AUTOSAR XML (schema 00044)
package /E40_Platform_System_SystemPackage/Components
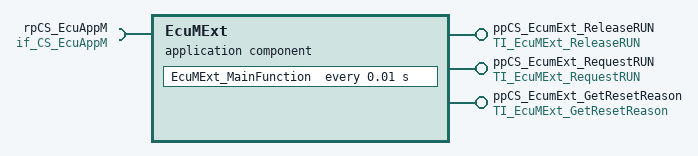
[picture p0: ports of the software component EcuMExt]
  application sw component type EcuMExt
    provide port ppCS_EcumExt_ReleaseRUN: server-com-spec{operation=ReleaseRUN, queue-length=1}, provided-interface=TI_EcuMExt_ReleaseRUN
    provide port ppCS_EcumExt_RequestRUN: server-com-spec{operation=RequestRUN, queue-length=1}, provided-interface=TI_EcuMExt_RequestRUN
    require port rpCS_EcuAppM: required-com-specs=[EcuAppM_SetWakeupSources, Init], required-interface=if_CS_EcuAppM
    provide port ppCS_EcumExt_GetResetReason: server-com-spec{operation=GetResetReason, queue-length=1}, provided-interface=TI_EcuMExt_GetResetReason
    behavior IB_EcuMExt
      timing event TEEcuMExt_MainFunction: start-on-event=EcuMExt_MainFunction, period=0.01
      operation invoked event OIE_ppCS_EcumExt_ReleaseRUN_EcuMExt_ReleaseRUNTrigByReleaseRUN: start-on-event=EcuMExt_ReleaseRUN, operation=ppCS_EcumExt_ReleaseRUN.ReleaseRUN
      operation invoked event OIE_ppCS_EcumExt_RequestRUN_EcuMExt_RequestRUNTrigByRequestRUN: start-on-event=EcuMExt_RequestRUN, operation=ppCS_EcumExt_RequestRUN.RequestRUN
      operation invoked event OIE_ppCS_EcumExt_GetResetReason_EcuMExt_GetResetReasonTrigByGetResetReason: start-on-event=EcuMExt_GetResetReason, operation=ppCS_EcumExt_GetResetReason.GetResetReason
      port-api-options:
        enable-take-address=false, indirect-api=false, port=ppCS_EcumExt_ReleaseRUN
        enable-take-address=false, indirect-api=false, port=ppCS_EcumExt_RequestRUN
        enable-take-address=false, indirect-api=false, port=rpCS_EcuAppM
        enable-take-address=false, indirect-api=false, port=ppCS_EcumExt_GetResetReason
      4 x runnable, all with can-be-invoked-concurrently=true:
        EcuMExt_MainFunction
          sync call OA_rpCS_EcuAppM_Init: operation=rpCS_EcuAppM.Init
          sync call OA_rpCS_EcuAppM_EcuAppM_SetWakeupSources: operation=rpCS_EcuAppM.EcuAppM_SetWakeupSources
        EcuMExt_ReleaseRUN
          sync call OA_rpCS_EcuAppM_Init: operation=rpCS_EcuAppM.Init
          sync call OA_rpCS_EcuAppM_EcuAppM_SetWakeupSources: operation=rpCS_EcuAppM.EcuAppM_SetWakeupSources
        EcuMExt_RequestRUN
          sync call OA_rpCS_EcuAppM_Init: operation=rpCS_EcuAppM.Init
          sync call OA_rpCS_EcuAppM_EcuAppM_SetWakeupSources: operation=rpCS_EcuAppM.EcuAppM_SetWakeupSources
        EcuMExt_GetResetReason
          sync call OA_rpCS_EcuAppM_Init: operation=rpCS_EcuAppM.Init
          sync call OA_rpCS_EcuAppM_EcuAppM_SetWakeupSources: operation=rpCS_EcuAppM.EcuAppM_SetWakeupSources
  swc implementation IMPL_EcuMExt: behavior=IB_EcuMExt
